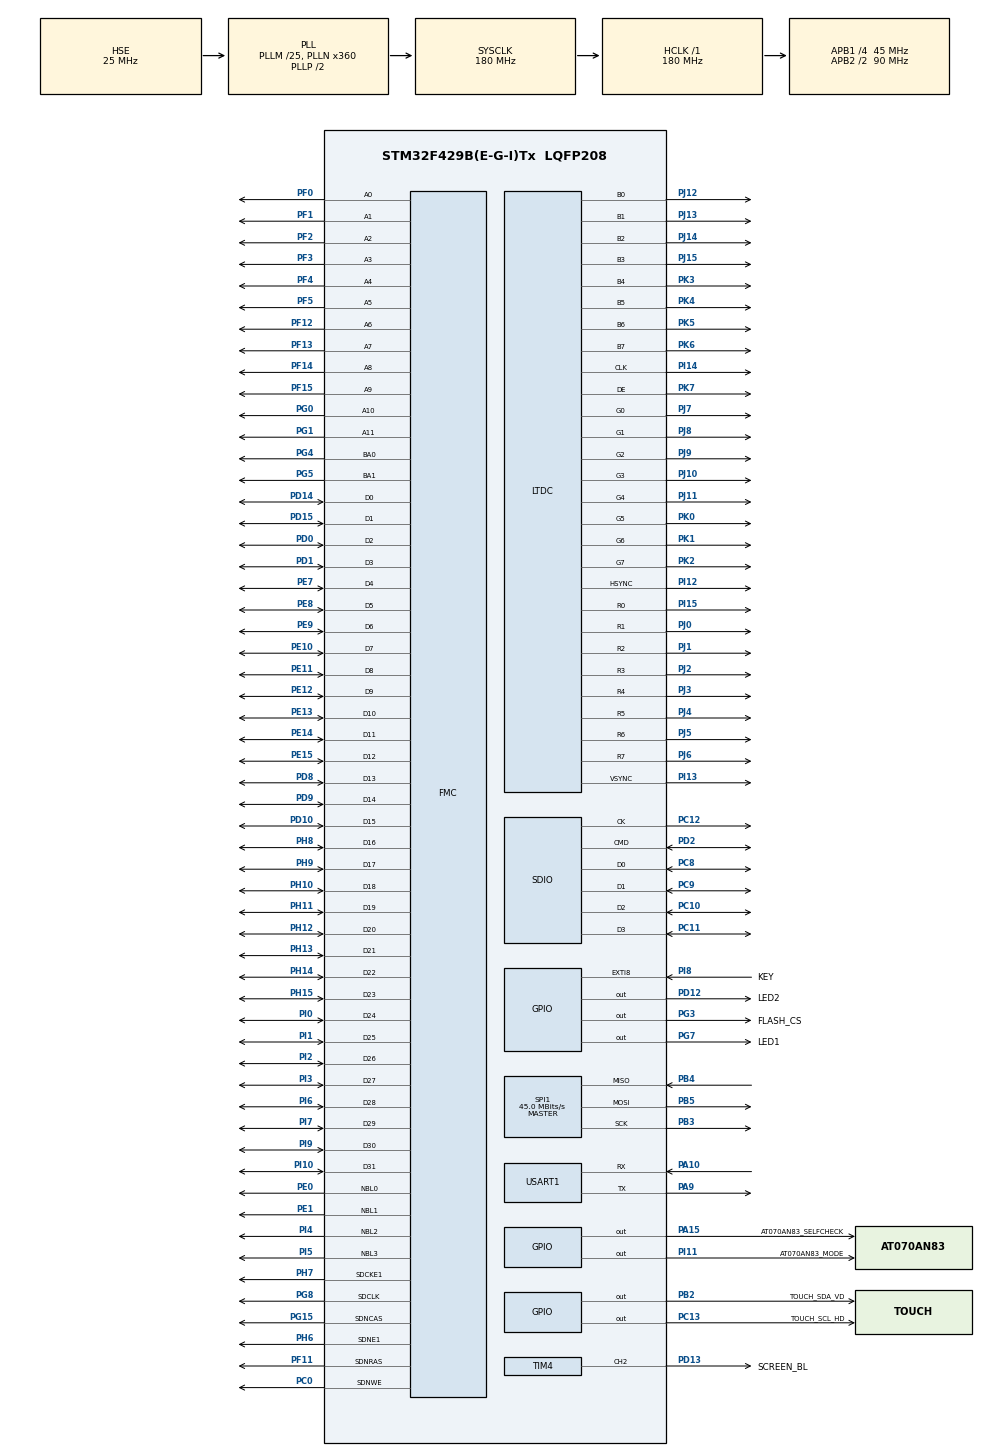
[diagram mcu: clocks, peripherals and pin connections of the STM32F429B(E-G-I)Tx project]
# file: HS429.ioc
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Dma.MEMTOMEM.2.Direction=DMA_MEMORY_TO_MEMORY
Dma.MEMTOMEM.2.FIFOMode=DMA_FIFOMODE_ENABLE
Dma.MEMTOMEM.2.FIFOThreshold=DMA_FIFO_THRESHOLD_FULL
Dma.MEMTOMEM.2.Instance=DMA2_Stream0
Dma.MEMTOMEM.2.MemBurst=DMA_MBURST_SINGLE
Dma.MEMTOMEM.2.MemDataAlignment=DMA_MDATAALIGN_BYTE
Dma.MEMTOMEM.2.MemInc=DMA_MINC_ENABLE
Dma.MEMTOMEM.2.Mode=DMA_NORMAL
Dma.MEMTOMEM.2.PeriphBurst=DMA_PBURST_SINGLE
Dma.MEMTOMEM.2.PeriphDataAlignment=DMA_PDATAALIGN_BYTE
Dma.MEMTOMEM.2.PeriphInc=DMA_PINC_ENABLE
Dma.MEMTOMEM.2.Priority=DMA_PRIORITY_MEDIUM
Dma.Request0=SDIO_RX
Dma.Request1=SDIO_TX
Dma.Request2=MEMTOMEM
Dma.SDIO_RX.0.Direction=DMA_PERIPH_TO_MEMORY
Dma.SDIO_RX.0.FIFOMode=DMA_FIFOMODE_ENABLE
Dma.SDIO_RX.0.FIFOThreshold=DMA_FIFO_THRESHOLD_FULL
Dma.SDIO_RX.0.Instance=DMA2_Stream3
Dma.SDIO_RX.0.MemBurst=DMA_MBURST_INC4
Dma.SDIO_RX.0.MemDataAlignment=DMA_MDATAALIGN_WORD
Dma.SDIO_RX.0.MemInc=DMA_MINC_ENABLE
Dma.SDIO_RX.0.Mode=DMA_PFCTRL
Dma.SDIO_RX.0.PeriphBurst=DMA_PBURST_INC4
Dma.SDIO_RX.0.PeriphDataAlignment=DMA_PDATAALIGN_WORD
Dma.SDIO_RX.0.PeriphInc=DMA_PINC_DISABLE
Dma.SDIO_RX.0.Priority=DMA_PRIORITY_LOW
Dma.SDIO_TX.1.Direction=DMA_MEMORY_TO_PERIPH
Dma.SDIO_TX.1.FIFOMode=DMA_FIFOMODE_ENABLE
Dma.SDIO_TX.1.FIFOThreshold=DMA_FIFO_THRESHOLD_FULL
Dma.SDIO_TX.1.Instance=DMA2_Stream6
Dma.SDIO_TX.1.MemBurst=DMA_MBURST_INC4
Dma.SDIO_TX.1.MemDataAlignment=DMA_MDATAALIGN_WORD
Dma.SDIO_TX.1.MemInc=DMA_MINC_ENABLE
Dma.SDIO_TX.1.Mode=DMA_PFCTRL
Dma.SDIO_TX.1.PeriphBurst=DMA_PBURST_INC4
Dma.SDIO_TX.1.PeriphDataAlignment=DMA_PDATAALIGN_WORD
Dma.SDIO_TX.1.PeriphInc=DMA_PINC_DISABLE
Dma.SDIO_TX.1.Priority=DMA_PRIORITY_LOW
FATFS._CODE_PAGE=437
FATFS._FS_RPATH=2
FATFS._MAX_SS=512
FATFS._MIN_SS=512
FATFS._USE_CHMOD=0
FATFS._USE_LABEL=0
FMC.CASLatency1=FMC_SDRAM_CAS_LATENCY_3
FMC.ExitSelfRefreshDelay1=7
FMC.LoadToActiveDelay1=2
FMC.RCDDelay1=2
FMC.RPDelay1=2
FMC.RPDelay2=2
FMC.ReadBurst1=FMC_SDRAM_RBURST_ENABLE
FMC.ReadBurst2=FMC_SDRAM_RBURST_ENABLE
FMC.ReadPipeDelay1=FMC_SDRAM_RPIPE_DELAY_1
FMC.ReadPipeDelay2=FMC_SDRAM_RPIPE_DELAY_1
FMC.RowCycleDelay1=7
FMC.RowCycleDelay2=7
FMC.SDClockPeriod1=FMC_SDRAM_CLOCK_PERIOD_2
FMC.SDClockPeriod2=FMC_SDRAM_CLOCK_PERIOD_2
FMC.SelfRefreshTime1=4
FMC.WriteRecoveryTime1=3
FREERTOS.Tasks01=defaultTask,0,512,StartDefaultTask,Default,NULL,Dynamic,NULL,NULL
FREERTOS.configTOTAL_HEAP_SIZE=102400
GRAPHICS.Check_OTM8009A_PixelFormat-STemWin_F429_439=1
GRAPHICS.DMA2D_Graphics-STemWin_F429_439=0
GRAPHICS.EA_1_Apptype=Window
GRAPHICS.EA_1_executable_name-STemWin_F429_439=GUIBuilder.exe
GRAPHICS.GUI_DefaultFont=Font8x16
GRAPHICS.GUI_NUM_LAYERS-STemWin_F429_439=1
GRAPHICS.GUI_Num_KBYTES=512
GRAPHICS.GUI_RGB_ORDERING=ARGB
GRAPHICS.LIN_Color_Conversion_Layer0=GUICC_M565
GRAPHICS.LIN_Frame_Buffer_Depth_Layer0-STemWin_F429_439=16
GRAPHICS.Num_MultBuffers=1
GRAPHICS.OPTIM_OS_use-STemWin_F429_439=2
GRAPHICS.USE_Embedded_Wizard-STemWin_F429_439=0
GRAPHICS.USE_STTouchGFX-STemWin_F429_439=0
GRAPHICS.UseGUIBuilder=Enabled
GRAPHICS.Use_SDRAM-STemWin_F429_439=SDRAM1_BANK2
GRAPHICS.Use_ili9341=0
GRAPHICS.Use_ili9341_Check-STemWin_F429_439=0
GRAPHICS.Xsize_PHYS=800
GRAPHICS.Ysize_PHYS=480
LTDC.ActiveW=800
LTDC.Alpha_L0=0xff
LTDC.Alpha_L1=0x7f
LTDC.BlendingFactor1_L1=LTDC_BLENDING_FACTOR1_CA
LTDC.BlendingFactor2_L1=LTDC_BLENDING_FACTOR2_CA
LTDC.FBStartAdress_L0=0xD0D00000
LTDC.FBStartAdress_L1=0xD0F00000
LTDC.HBP=46
LTDC.HFP=200
LTDC.HSync=20
LTDC.ImageHeight_L0=480
LTDC.ImageHeight_L1=480
LTDC.ImageWidth_L0=800
LTDC.ImageWidth_L1=800
LTDC.Layers=0
LTDC.PixelFormat_L0=LTDC_PIXEL_FORMAT_RGB565
LTDC.PixelFormat_L1=LTDC_PIXEL_FORMAT_RGB565
LTDC.VBP=23
LTDC.VFP=22
LTDC.VSync=3
LTDC.WindowX1_L0=800
LTDC.WindowX1_L1=800
LTDC.WindowY1_L0=480
LTDC.WindowY1_L1=480
Mcu.Family=STM32F4
Mcu.Name=STM32F429B(E-G-I)Tx
Mcu.Package=LQFP208
NVIC.DMA2_Stream3_IRQn=true\:5\:0\:false\:false\:true\:true\:false
NVIC.DMA2_Stream6_IRQn=true\:5\:0\:false\:false\:true\:true\:false
NVIC.EXTI9_5_IRQn=true\:5\:0\:false\:false\:true\:true\:true
NVIC.PriorityGroup=NVIC_PRIORITYGROUP_4
NVIC.SDIO_IRQn=true\:5\:0\:true\:false\:true\:true\:true
NVIC.TIM8_TRG_COM_TIM14_IRQn=true\:0\:0\:false\:false\:true\:false\:false
NVIC.TimeBase=TIM8_TRG_COM_TIM14_IRQn
NVIC.TimeBaseIP=TIM14
NVIC.USART1_IRQn=true\:5\:0\:false\:false\:true\:true\:true
PA10.Mode=Asynchronous
PA10.Signal=USART1_RX
PA13.Mode=Serial_Wire
PA13.Signal=SYS_JTMS-SWDIO
PA14.Mode=Serial_Wire
PA14.Signal=SYS_JTCK-SWCLK
PA15.GPIO_Label=AT070AN83_SELFCHECK
PA15.Signal=GPIO_Output
PA9.Mode=Asynchronous
PA9.Signal=USART1_TX
PB2/BOOT1.GPIO_Label=TOUCH_SDA_VD
PB2/BOOT1.GPIO_Speed=GPIO_SPEED_FREQ_VERY_HIGH
PB2/BOOT1.Signal=GPIO_Output
PB3.GPIO_PuPd=GPIO_PULLUP
PB3.Mode=Full_Duplex_Master
PB3.Signal=SPI1_SCK
PB4.GPIO_PuPd=GPIO_PULLUP
PB4.Mode=Full_Duplex_Master
PB4.Signal=SPI1_MISO
PB5.GPIO_PuPd=GPIO_PULLUP
PB5.Mode=Full_Duplex_Master
PB5.Signal=SPI1_MOSI
PC0.Signal=FMC_SDNWE
PC10.Mode=SD_4_bits_Wide_bus
PC10.Signal=SDIO_D2
PC11.Mode=SD_4_bits_Wide_bus
PC11.Signal=SDIO_D3
PC12.Mode=SD_4_bits_Wide_bus
PC12.Signal=SDIO_CK
PC13.GPIO_Label=TOUCH_SCL_HD
PC13.PinState=GPIO_PIN_SET
PC13.Signal=GPIO_Output
PC14/OSC32_IN.Mode=LSE-External-Oscillator
PC14/OSC32_IN.Signal=RCC_OSC32_IN
PC15/OSC32_OUT.Mode=LSE-External-Oscillator
PC15/OSC32_OUT.Signal=RCC_OSC32_OUT
PC8.Mode=SD_4_bits_Wide_bus
PC8.Signal=SDIO_D0
PC9.Mode=SD_4_bits_Wide_bus
PC9.Signal=SDIO_D1
PD0.Signal=FMC_D2_DA2
PD1.Signal=FMC_D3_DA3
PD10.Signal=FMC_D15_DA15
PD12.GPIO_Label=LED2
PD12.GPIO_Speed=GPIO_SPEED_FREQ_MEDIUM
PD12.Signal=GPIO_Output
PD13.GPIO_Label=SCREEN_BL
PD13.GPIO_Speed=GPIO_SPEED_FREQ_VERY_HIGH
PD13.Signal=S_TIM4_CH2
PD14.Signal=FMC_D0_DA0
PD15.Signal=FMC_D1_DA1
PD2.Mode=SD_4_bits_Wide_bus
PD2.Signal=SDIO_CMD
PD8.Signal=FMC_D13_DA13
PD9.Signal=FMC_D14_DA14
PE0.Signal=FMC_NBL0
PE1.Signal=FMC_NBL1
PE10.Signal=FMC_D7_DA7
PE11.Signal=FMC_D8_DA8
PE12.Signal=FMC_D9_DA9
PE13.Signal=FMC_D10_DA10
PE14.Signal=FMC_D11_DA11
PE15.Signal=FMC_D12_DA12
PE7.Signal=FMC_D4_DA4
PE8.Signal=FMC_D5_DA5
PE9.Signal=FMC_D6_DA6
PF0.Signal=FMC_A0
PF1.Signal=FMC_A1
PF11.Signal=FMC_SDNRAS
PF12.Signal=FMC_A6
PF13.Signal=FMC_A7
PF14.Signal=FMC_A8
PF15.Signal=FMC_A9
PF2.Signal=FMC_A2
PF3.Signal=FMC_A3
PF4.Signal=FMC_A4
PF5.Signal=FMC_A5
PG0.Signal=FMC_A10
PG1.Signal=FMC_A11
PG15.Signal=FMC_SDNCAS
PG3.GPIO_Label=FLASH_CS
PG3.GPIO_Speed=GPIO_SPEED_FREQ_HIGH
PG3.Signal=GPIO_Output
PG4.Signal=FMC_A14_BA0
PG5.Signal=FMC_A15_BA1
PG7.GPIO_Label=LED1
PG7.GPIO_Speed=GPIO_SPEED_FREQ_MEDIUM
PG7.Signal=GPIO_Output
PG8.Signal=FMC_SDCLK
PH0/OSC_IN.Mode=HSE-External-Oscillator
PH0/OSC_IN.Signal=RCC_OSC_IN
PH1/OSC_OUT.Mode=HSE-External-Oscillator
PH1/OSC_OUT.Signal=RCC_OSC_OUT
PH10.Signal=FMC_D18
PH11.Signal=FMC_D19
PH12.Signal=FMC_D20
PH13.Signal=FMC_D21
PH14.Signal=FMC_D22
PH15.Signal=FMC_D23
PH6.Mode=SdramChipSelect2_1
PH6.Signal=FMC_SDNE1
PH7.Mode=SdramChipSelect2_1
PH7.Signal=FMC_SDCKE1
PH8.Signal=FMC_D16
PH9.Signal=FMC_D17
PI0.Signal=FMC_D24
PI1.Signal=FMC_D25
PI10.Signal=FMC_D31
PI11.GPIO_Label=AT070AN83_MODE
PI11.PinState=GPIO_PIN_SET
PI11.Signal=GPIO_Output
PI12.GPIO_Speed=GPIO_SPEED_FREQ_VERY_HIGH
PI12.Mode=RGB888
PI12.Signal=LTDC_HSYNC
PI13.GPIO_Speed=GPIO_SPEED_FREQ_VERY_HIGH
PI13.Mode=RGB888
PI13.Signal=LTDC_VSYNC
PI14.GPIO_Speed=GPIO_SPEED_FREQ_VERY_HIGH
PI14.Mode=RGB888
PI14.Signal=LTDC_CLK
PI15.GPIO_Speed=GPIO_SPEED_FREQ_VERY_HIGH
PI15.Mode=RGB888
PI15.Signal=LTDC_R0
PI2.Signal=FMC_D26
PI3.Signal=FMC_D27
PI4.Signal=FMC_NBL2
PI5.Signal=FMC_NBL3
PI6.Signal=FMC_D28
PI7.Signal=FMC_D29
PI8.GPIO_Label=KEY
PI8.GPIO_ModeDefaultEXTI=GPIO_MODE_IT_FALLING
PI8.GPIO_PuPd=GPIO_PULLUP
PI8.Signal=GPXTI8
PI9.Signal=FMC_D30
PJ0.GPIO_Speed=GPIO_SPEED_FREQ_VERY_HIGH
PJ0.Mode=RGB888
PJ0.Signal=LTDC_R1
PJ1.GPIO_Speed=GPIO_SPEED_FREQ_VERY_HIGH
PJ1.Mode=RGB888
PJ1.Signal=LTDC_R2
PJ10.GPIO_Speed=GPIO_SPEED_FREQ_VERY_HIGH
PJ10.Mode=RGB888
PJ10.Signal=LTDC_G3
PJ11.GPIO_Speed=GPIO_SPEED_FREQ_VERY_HIGH
PJ11.Mode=RGB888
PJ11.Signal=LTDC_G4
PJ12.GPIO_Speed=GPIO_SPEED_FREQ_VERY_HIGH
PJ12.Mode=RGB888
PJ12.Signal=LTDC_B0
PJ13.GPIO_Speed=GPIO_SPEED_FREQ_VERY_HIGH
PJ13.Mode=RGB888
PJ13.Signal=LTDC_B1
PJ14.GPIO_Speed=GPIO_SPEED_FREQ_VERY_HIGH
PJ14.Mode=RGB888
PJ14.Signal=LTDC_B2
PJ15.GPIO_Speed=GPIO_SPEED_FREQ_VERY_HIGH
PJ15.Mode=RGB888
PJ15.Signal=LTDC_B3
PJ2.GPIO_Speed=GPIO_SPEED_FREQ_VERY_HIGH
PJ2.Mode=RGB888
PJ2.Signal=LTDC_R3
PJ3.GPIO_Speed=GPIO_SPEED_FREQ_VERY_HIGH
PJ3.Mode=RGB888
PJ3.Signal=LTDC_R4
PJ4.GPIO_Speed=GPIO_SPEED_FREQ_VERY_HIGH
PJ4.Mode=RGB888
PJ4.Signal=LTDC_R5
PJ5.GPIO_Speed=GPIO_SPEED_FREQ_VERY_HIGH
PJ5.Mode=RGB888
PJ5.Signal=LTDC_R6
PJ6.GPIO_Speed=GPIO_SPEED_FREQ_VERY_HIGH
PJ6.Mode=RGB888
PJ6.Signal=LTDC_R7
PJ7.GPIO_Speed=GPIO_SPEED_FREQ_VERY_HIGH
PJ7.Mode=RGB888
PJ7.Signal=LTDC_G0
PJ8.GPIO_Speed=GPIO_SPEED_FREQ_VERY_HIGH
PJ8.Mode=RGB888
PJ8.Signal=LTDC_G1
PJ9.GPIO_Speed=GPIO_SPEED_FREQ_VERY_HIGH
PJ9.Mode=RGB888
PJ9.Signal=LTDC_G2
PK0.GPIO_Speed=GPIO_SPEED_FREQ_VERY_HIGH
PK0.Mode=RGB888
PK0.Signal=LTDC_G5
PK1.GPIO_Speed=GPIO_SPEED_FREQ_VERY_HIGH
PK1.Mode=RGB888
PK1.Signal=LTDC_G6
PK2.GPIO_Speed=GPIO_SPEED_FREQ_VERY_HIGH
PK2.Mode=RGB888
PK2.Signal=LTDC_G7
PK3.GPIO_Speed=GPIO_SPEED_FREQ_VERY_HIGH
PK3.Mode=RGB888
PK3.Signal=LTDC_B4
PK4.GPIO_Speed=GPIO_SPEED_FREQ_VERY_HIGH
PK4.Mode=RGB888
PK4.Signal=LTDC_B5
PK5.GPIO_Speed=GPIO_SPEED_FREQ_VERY_HIGH
PK5.Mode=RGB888
PK5.Signal=LTDC_B6
PK6.GPIO_Speed=GPIO_SPEED_FREQ_VERY_HIGH
PK6.Mode=RGB888
PK6.Signal=LTDC_B7
PK7.GPIO_Speed=GPIO_SPEED_FREQ_VERY_HIGH
PK7.Mode=RGB888
PK7.Signal=LTDC_DE
ProjectManager.HeapSize=0x2000
ProjectManager.StackSize=0x4000
ProjectManager.TargetToolchain=MDK-ARM V5
RCC.48MHZClocksFreq_Value=45000000
RCC.AHBFreq_Value=180000000
RCC.APB1CLKDivider=RCC_HCLK_DIV4
RCC.APB1Freq_Value=45000000
RCC.APB1TimFreq_Value=90000000
RCC.APB2CLKDivider=RCC_HCLK_DIV2
RCC.APB2Freq_Value=90000000
RCC.APB2TimFreq_Value=180000000
RCC.CortexFreq_Value=180000000
RCC.HCLKFreq_Value=180000000
RCC.HSE_VALUE=25000000
RCC.HSI_VALUE=16000000
RCC.PLLM=25
RCC.PLLN=360
RCC.PLLQ=8
RCC.PLLSAIN=198
RCC.PLLSAIR=3
RCC.PLLSourceVirtual=RCC_PLLSOURCE_HSE
RCC.RCC_RTC_Clock_Source=RCC_RTCCLKSOURCE_LSE
RCC.RCC_RTC_Clock_SourceVirtual=RCC_RTCCLKSOURCE_LSE
RCC.SYSCLKFreq_VALUE=180000000
RCC.SYSCLKSource=RCC_SYSCLKSOURCE_PLLCLK
RCC.VCOOutputFreq_Value=360000000
SDIO.ClockDiv=4
SH.FMC_A0.0=FMC_A0,12b-sda1
SH.FMC_A1.0=FMC_A1,12b-sda1
SH.FMC_A10.0=FMC_A10,12b-sda1
SH.FMC_A11.0=FMC_A11,12b-sda1
SH.FMC_A14_BA0.0=FMC_BA0,FourSdramBanks1
SH.FMC_A15_BA1.0=FMC_BA1,FourSdramBanks1
SH.FMC_A2.0=FMC_A2,12b-sda1
SH.FMC_A3.0=FMC_A3,12b-sda1
SH.FMC_A4.0=FMC_A4,12b-sda1
SH.FMC_A5.0=FMC_A5,12b-sda1
SH.FMC_A6.0=FMC_A6,12b-sda1
SH.FMC_A7.0=FMC_A7,12b-sda1
SH.FMC_A8.0=FMC_A8,12b-sda1
SH.FMC_A9.0=FMC_A9,12b-sda1
SH.FMC_D0_DA0.0=FMC_D0,sd-32b-d1
SH.FMC_D10_DA10.0=FMC_D10,sd-32b-d1
SH.FMC_D11_DA11.0=FMC_D11,sd-32b-d1
SH.FMC_D12_DA12.0=FMC_D12,sd-32b-d1
SH.FMC_D13_DA13.0=FMC_D13,sd-32b-d1
SH.FMC_D14_DA14.0=FMC_D14,sd-32b-d1
SH.FMC_D15_DA15.0=FMC_D15,sd-32b-d1
SH.FMC_D16.0=FMC_D16,sd-32b-d1
SH.FMC_D17.0=FMC_D17,sd-32b-d1
SH.FMC_D18.0=FMC_D18,sd-32b-d1
SH.FMC_D19.0=FMC_D19,sd-32b-d1
SH.FMC_D1_DA1.0=FMC_D1,sd-32b-d1
SH.FMC_D20.0=FMC_D20,sd-32b-d1
SH.FMC_D21.0=FMC_D21,sd-32b-d1
SH.FMC_D22.0=FMC_D22,sd-32b-d1
SH.FMC_D23.0=FMC_D23,sd-32b-d1
SH.FMC_D24.0=FMC_D24,sd-32b-d1
SH.FMC_D25.0=FMC_D25,sd-32b-d1
SH.FMC_D26.0=FMC_D26,sd-32b-d1
SH.FMC_D27.0=FMC_D27,sd-32b-d1
SH.FMC_D28.0=FMC_D28,sd-32b-d1
SH.FMC_D29.0=FMC_D29,sd-32b-d1
SH.FMC_D2_DA2.0=FMC_D2,sd-32b-d1
SH.FMC_D30.0=FMC_D30,sd-32b-d1
SH.FMC_D31.0=FMC_D31,sd-32b-d1
SH.FMC_D3_DA3.0=FMC_D3,sd-32b-d1
SH.FMC_D4_DA4.0=FMC_D4,sd-32b-d1
SH.FMC_D5_DA5.0=FMC_D5,sd-32b-d1
SH.FMC_D6_DA6.0=FMC_D6,sd-32b-d1
SH.FMC_D7_DA7.0=FMC_D7,sd-32b-d1
SH.FMC_D8_DA8.0=FMC_D8,sd-32b-d1
SH.FMC_D9_DA9.0=FMC_D9,sd-32b-d1
SH.FMC_NBL0.0=FMC_NBL0,Sd4ByteEnable1
SH.FMC_NBL1.0=FMC_NBL1,Sd4ByteEnable1
SH.FMC_NBL2.0=FMC_NBL2,Sd4ByteEnable1
SH.FMC_NBL3.0=FMC_NBL3,Sd4ByteEnable1
SH.FMC_SDCLK.0=FMC_SDCLK,12b-sda1
SH.FMC_SDNCAS.0=FMC_SDNCAS,12b-sda1
SH.FMC_SDNRAS.0=FMC_SDNRAS,12b-sda1
SH.FMC_SDNWE.0=FMC_SDNWE,12b-sda1
SH.S_TIM4_CH2.0=TIM4_CH2,PWM Generation2 CH2
SPI1.BaudRatePrescaler=SPI_BAUDRATEPRESCALER_2
SPI1.CLKPhase=SPI_PHASE_2EDGE
SPI1.CLKPolarity=SPI_POLARITY_HIGH
SPI1.CalculateBaudRate=45.0 MBits/s
SPI1.Direction=SPI_DIRECTION_2LINES
SPI1.Mode=SPI_MODE_MASTER
SPI1.VirtualType=VM_MASTER
TIM4.Channel-PWM\ Generation2\ CH2=TIM_CHANNEL_2
TIM4.Period=5000
TIM4.Prescaler=89
TIM4.Pulse-PWM\ Generation2\ CH2=2000
USART1.VirtualMode=VM_ASYNC
VP_CRC_VS_CRC.Mode=CRC_Activate
VP_FATFS_VS_Generic.Mode=User_defined
VP_FATFS_VS_SDIO.Mode=SDIO
VP_FREERTOS_VS_ENABLE.Mode=Enabled
VP_GRAPHICS_VS-DisplayInterface-LTDC.Mode=Display Parallel Interface using LTDC
VP_GRAPHICS_VS-STemWin.Mode=STemWin_F429_439
VP_RNG_VS_RNG.Mode=RNG_Activate
VP_RTC_VS_RTC_Activate.Mode=RTC_Enabled
VP_SYS_VS_tim14.Mode=TIM14
board=custom

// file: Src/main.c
/**
  ******************************************************************************
  * @file           : main.c
  * @brief          : Main program body
  ******************************************************************************
  * This notice applies to any and all portions of this file
  * that are not between comment pairs USER CODE BEGIN and
  * USER CODE END. Other portions of this file, whether
  * inserted by the user or by software development tools
  * are owned by their respective copyright owners.
  *
  * Copyright (c) 2018 STMicroelectronics International N.V.
  * All rights reserved.
  *
  * Redistribution and use in source and binary forms, with or without
  * modification, are permitted, provided that the following conditions are met:
  *
  * 1. Redistribution of source code must retain the above copyright notice,
  *    this list of conditions and the following disclaimer.
  * 2. Redistributions in binary form must reproduce the above copyright notice,
  *    this list of conditions and the following disclaimer in the documentation
  *    and/or other materials provided with the distribution.
  * 3. Neither the name of STMicroelectronics nor the names of other
  *    contributors to this software may be used to endorse or promote products
  *    derived from this software without specific written permission.
  * 4. This software, including modifications and/or derivative works of this
  *    software, must execute solely and exclusively on microcontroller or
  *    microprocessor devices manufactured by or for STMicroelectronics.
  * 5. Redistribution and use of this software other than as permitted under
  *    this license is void and will automatically terminate your rights under
  *    this license.
  *
  * THIS SOFTWARE IS PROVIDED BY STMICROELECTRONICS AND CONTRIBUTORS "AS IS"
  * AND ANY EXPRESS, IMPLIED OR STATUTORY WARRANTIES, INCLUDING, BUT NOT
  * LIMITED TO, THE IMPLIED WARRANTIES OF MERCHANTABILITY, FITNESS FOR A
  * PARTICULAR PURPOSE AND NON-INFRINGEMENT OF THIRD PARTY INTELLECTUAL PROPERTY
  * RIGHTS ARE DISCLAIMED TO THE FULLEST EXTENT PERMITTED BY LAW. IN NO EVENT
  * SHALL STMICROELECTRONICS OR CONTRIBUTORS BE LIABLE FOR ANY DIRECT, INDIRECT,
  * INCIDENTAL, SPECIAL, EXEMPLARY, OR CONSEQUENTIAL DAMAGES (INCLUDING, BUT NOT
  * LIMITED TO, PROCUREMENT OF SUBSTITUTE GOODS OR SERVICES; LOSS OF USE, DATA,
  * OR PROFITS; OR BUSINESS INTERRUPTION) HOWEVER CAUSED AND ON ANY THEORY OF
  * LIABILITY, WHETHER IN CONTRACT, STRICT LIABILITY, OR TORT (INCLUDING
  * NEGLIGENCE OR OTHERWISE) ARISING IN ANY WAY OUT OF THE USE OF THIS SOFTWARE,
  * EVEN IF ADVISED OF THE POSSIBILITY OF SUCH DAMAGE.
  *
  ******************************************************************************
  */
#include "main.h"
#include "stm32f4xx_hal.h"
#include "cmsis_os.h"
#include "crc.h"
#include "dma.h"
#include "fatfs.h"
#include "rng.h"
#include "rtc.h"
#include "sdio.h"
#include "spi.h"
#include "tim.h"
#include "usart.h"
#include "gpio.h"

/* USER CODE BEGIN Includes */
#include "bsp_driver_flash.h"
#include "mem.h"
#include "touch.h"

/* USER CODE END Includes */

/* USER CODE BEGIN PV */
/* Private variables ---------------------------------------------------------*/
extern uint8_t uartRevValue;

/* USER CODE END PV */

void SystemClock_Config(void);
void MX_FREERTOS_Init(void);
extern void GRAPHICS_HW_Init(void);
extern void GRAPHICS_Init(void);
extern void GRAPHICS_MainTask(void);

/* USER CODE BEGIN PFP */
/* Private function prototypes -----------------------------------------------*/

/* USER CODE END PFP */

/* USER CODE BEGIN 0 */
int fputc(int ch, FILE* stream)
{
    UART1_PrintChar((uint8_t)ch);
    return ch;
}
/* USER CODE END 0 */

int main(void)
{

  /* MCU Configuration----------------------------------------------------------*/

  /* Reset of all peripherals, Initializes the Flash interface and the Systick. */
  HAL_Init();

  /* Configure the system clock */
  SystemClock_Config();

  /* Initialize all configured peripherals */
  MX_GPIO_Init();
  MX_DMA_Init();
  MX_RTC_Init();
  MX_SDIO_SD_Init();
  MX_USART1_UART_Init();
  MX_CRC_Init();
  MX_SPI1_Init();
  MX_TIM4_Init();
  MX_RNG_Init();
  /* USER CODE BEGIN 2 */
    //附加启动
    HAL_UART_Receive_IT(&huart1, &uartRevValue, 1);
    UART1_PrintLn("UART1 Open...");
    TOUCH_Init();   //初始化触摸屏
    HAL_TIM_PWM_Start(&htim4,TIM_CHANNEL_2);  //40%亮度

    //用户代码
    HAL_GPIO_WritePin(LED1_GPIO_Port,LED1_Pin,GPIO_PIN_SET);
    mallocInit();

  /* USER CODE END 2 */

/* Initialise the graphical hardware */
  GRAPHICS_HW_Init();

  /* Initialise the graphical stack engine */
  GRAPHICS_Init();

  /* Call init function for freertos objects (in freertos.c) */
  MX_FREERTOS_Init();

  /* Start scheduler */
  osKernelStart();

  /* We should never get here as control is now taken by the scheduler */

  /* Infinite loop */
  while (1)
  {

  }

}

void SystemClock_Config(void)
{

  RCC_OscInitTypeDef RCC_OscInitStruct;
  RCC_ClkInitTypeDef RCC_ClkInitStruct;
  RCC_PeriphCLKInitTypeDef PeriphClkInitStruct;

    /**Configure the main internal regulator output voltage
    */
  __HAL_RCC_PWR_CLK_ENABLE();

  __HAL_PWR_VOLTAGESCALING_CONFIG(PWR_REGULATOR_VOLTAGE_SCALE1);

    /**Initializes the CPU, AHB and APB busses clocks
    */
  RCC_OscInitStruct.OscillatorType = RCC_OSCILLATORTYPE_HSE|RCC_OSCILLATORTYPE_LSE;
  RCC_OscInitStruct.HSEState = RCC_HSE_ON;
  RCC_OscInitStruct.LSEState = RCC_LSE_ON;
  RCC_OscInitStruct.PLL.PLLState = RCC_PLL_ON;
  RCC_OscInitStruct.PLL.PLLSource = RCC_PLLSOURCE_HSE;
  RCC_OscInitStruct.PLL.PLLM = 25;
  RCC_OscInitStruct.PLL.PLLN = 360;
  RCC_OscInitStruct.PLL.PLLP = RCC_PLLP_DIV2;
  RCC_OscInitStruct.PLL.PLLQ = 8;
  if (HAL_RCC_OscConfig(&RCC_OscInitStruct) != HAL_OK)
  {
    _Error_Handler(__FILE__, __LINE__);
  }

    /**Activate the Over-Drive mode
    */
  if (HAL_PWREx_EnableOverDrive() != HAL_OK)
  {
    _Error_Handler(__FILE__, __LINE__);
  }

    /**Initializes the CPU, AHB and APB busses clocks
    */
  RCC_ClkInitStruct.ClockType = RCC_CLOCKTYPE_HCLK|RCC_CLOCKTYPE_SYSCLK
                              |RCC_CLOCKTYPE_PCLK1|RCC_CLOCKTYPE_PCLK2;
  RCC_ClkInitStruct.SYSCLKSource = RCC_SYSCLKSOURCE_PLLCLK;
  RCC_ClkInitStruct.AHBCLKDivider = RCC_SYSCLK_DIV1;
  RCC_ClkInitStruct.APB1CLKDivider = RCC_HCLK_DIV4;
  RCC_ClkInitStruct.APB2CLKDivider = RCC_HCLK_DIV2;

  if (HAL_RCC_ClockConfig(&RCC_ClkInitStruct, FLASH_LATENCY_5) != HAL_OK)
  {
    _Error_Handler(__FILE__, __LINE__);
  }

  PeriphClkInitStruct.PeriphClockSelection = RCC_PERIPHCLK_LTDC|RCC_PERIPHCLK_RTC;
  PeriphClkInitStruct.PLLSAI.PLLSAIN = 198;
  PeriphClkInitStruct.PLLSAI.PLLSAIR = 3;
  PeriphClkInitStruct.PLLSAIDivR = RCC_PLLSAIDIVR_2;
  PeriphClkInitStruct.RTCClockSelection = RCC_RTCCLKSOURCE_LSE;
  if (HAL_RCCEx_PeriphCLKConfig(&PeriphClkInitStruct) != HAL_OK)
  {
    _Error_Handler(__FILE__, __LINE__);
  }

    /**Configure the Systick interrupt time
    */
  HAL_SYSTICK_Config(HAL_RCC_GetHCLKFreq()/1000);

    /**Configure the Systick
    */
  HAL_SYSTICK_CLKSourceConfig(SYSTICK_CLKSOURCE_HCLK);

  /* SysTick_IRQn interrupt configuration */
  HAL_NVIC_SetPriority(SysTick_IRQn, 15, 0);
}

void HAL_TIM_PeriodElapsedCallback(TIM_HandleTypeDef *htim)
{
  if (htim->Instance == TIM14) {
    HAL_IncTick();
  }
}

void _Error_Handler(char *file, int line)
{
    while(1)
    {
    }
}

/************************ (C) COPYRIGHT STMicroelectronics *****END OF FILE****/

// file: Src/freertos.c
/* USER CODE BEGIN Header */
/**
  ******************************************************************************
  * File Name          : freertos.c
  * Description        : Code for freertos applications
  ******************************************************************************
  * This notice applies to any and all portions of this file
  * that are not between comment pairs USER CODE BEGIN and
  * USER CODE END. Other portions of this file, whether
  * inserted by the user or by software development tools
  * are owned by their respective copyright owners.
  *
  * Copyright (c) 2018 STMicroelectronics International N.V.
  * All rights reserved.
  *
  * Redistribution and use in source and binary forms, with or without
  * modification, are permitted, provided that the following conditions are met:
  *
  * 1. Redistribution of source code must retain the above copyright notice,
  *    this list of conditions and the following disclaimer.
  * 2. Redistributions in binary form must reproduce the above copyright notice,
  *    this list of conditions and the following disclaimer in the documentation
  *    and/or other materials provided with the distribution.
  * 3. Neither the name of STMicroelectronics nor the names of other
  *    contributors to this software may be used to endorse or promote products
  *    derived from this software without specific written permission.
  * 4. This software, including modifications and/or derivative works of this
  *    software, must execute solely and exclusively on microcontroller or
  *    microprocessor devices manufactured by or for STMicroelectronics.
  * 5. Redistribution and use of this software other than as permitted under
  *    this license is void and will automatically terminate your rights under
  *    this license.
  *
  * THIS SOFTWARE IS PROVIDED BY STMICROELECTRONICS AND CONTRIBUTORS "AS IS"
  * AND ANY EXPRESS, IMPLIED OR STATUTORY WARRANTIES, INCLUDING, BUT NOT
  * LIMITED TO, THE IMPLIED WARRANTIES OF MERCHANTABILITY, FITNESS FOR A
  * PARTICULAR PURPOSE AND NON-INFRINGEMENT OF THIRD PARTY INTELLECTUAL PROPERTY
  * RIGHTS ARE DISCLAIMED TO THE FULLEST EXTENT PERMITTED BY LAW. IN NO EVENT
  * SHALL STMICROELECTRONICS OR CONTRIBUTORS BE LIABLE FOR ANY DIRECT, INDIRECT,
  * INCIDENTAL, SPECIAL, EXEMPLARY, OR CONSEQUENTIAL DAMAGES (INCLUDING, BUT NOT
  * LIMITED TO, PROCUREMENT OF SUBSTITUTE GOODS OR SERVICES; LOSS OF USE, DATA,
  * OR PROFITS; OR BUSINESS INTERRUPTION) HOWEVER CAUSED AND ON ANY THEORY OF
  * LIABILITY, WHETHER IN CONTRACT, STRICT LIABILITY, OR TORT (INCLUDING
  * NEGLIGENCE OR OTHERWISE) ARISING IN ANY WAY OUT OF THE USE OF THIS SOFTWARE,
  * EVEN IF ADVISED OF THE POSSIBILITY OF SUCH DAMAGE.
  *
  ******************************************************************************
  */
/* USER CODE END Header */

#include "FreeRTOS.h"
#include "task.h"
#include "main.h"
#include "cmsis_os.h"

/* USER CODE BEGIN Includes */
#include "usart.h"
#include "fatfs.h"
#include "bsp_driver_flash.h"
/* USER CODE END Includes */

/* USER CODE BEGIN Variables */
FIL fil;

u8 datas[1024];
/* USER CODE END Variables */
osThreadId defaultTaskHandle;
osThreadId debugTaskHandle;

void StartDefaultTask(void const * argument);
void StartDebugTask(void const * argument);

extern void MX_FATFS_Init(void);
void MX_FREERTOS_Init(void); /* (MISRA C 2004 rule 8.1) */

void MX_FREERTOS_Init(void) {

  /* Create the thread(s) */
  /* definition and creation of defaultTask */
  osThreadDef(defaultTask, StartDefaultTask, osPriorityNormal, 0, 128);
  defaultTaskHandle = osThreadCreate(osThread(defaultTask), NULL);

  /* definition and creation of debugTask */
  osThreadDef(debugTask, StartDebugTask, osPriorityAboveNormal, 0, 128);
  debugTaskHandle = osThreadCreate(osThread(debugTask), NULL);

}

void StartDefaultTask(void const * argument)
{
  /* init code for FATFS */
  MX_FATFS_Init();

  /* USER CODE BEGIN StartDefaultTask */
    UART1_PrintLn("Default Task Started");
    osDelay(500);
    //=======================fatfs====================

    //FRESULT fr;
    //UART1_PrintLn("FatFS mount...");
    /*
    fr=f_mount(&SDFatFS,"0:",1);
    if(fr != FR_OK)
    {
        if(fr==FR_NO_FILESYSTEM)
        {
            UART1_PrintLn("FatFS SD format...");
            fr=f_mkfs("0:",FM_ANY,0,datas,sizeof(datas));
            if(fr != FR_OK)
                UART1_PrintDataLn("FatFS SD format fail:",fr);
        }
        else
            UART1_PrintDataLn("FatFS SD mount Fail:",fr);

    }
    else
    {
        UART1_PrintLn("FatFS SD mount Success");
    }

    fr=f_mount(&USERFatFS,"1:",1);
    if(fr != FR_OK)
    {
        if(fr==FR_NO_FILESYSTEM)
        {
            UART1_PrintLn("FatFS FLASH format...");
            fr=f_mkfs("1:",FM_ANY,0,datas,sizeof(datas));
            if(fr != FR_OK)
                UART1_PrintDataLn("FatFS FLASH format fail:",fr);
        }
        else
            UART1_PrintDataLn("FatFS FLASH mount Fail:",fr);

    }
    else
    {
        UART1_PrintLn("FatFS FLASH mount Success");
    }

    //�ļ�����

    u32 bw;
    //char line[100];
    fr=f_open(&fil,"1:m.txt",FA_WRITE|FA_CREATE_ALWAYS);
    if(fr==FR_OK)
    {

        UART1_PrintLn("Start write");
        fr=f_write(&fil,"ahhhhhh",5,&bw);
        if(fr!=FR_OK) UART1_PrintLn("write fail");
        f_close(&fil);

    }
    else UART1_PrintLn("create fail");

    //��Ŀ¼��ȡ
    DIR dir;
    FILINFO fno;
    fr=f_opendir(&dir,"1:");
    if(fr==FR_OK)
    {
        for(;;)
        {
            fr = f_readdir(&dir, &fno);
                if (fr != FR_OK || fno.fname[0] == 0)
                {
                    UART1_PrintLn("None");
                    break;
                }
            UART1_Print("Get file:");
            UART1_PrintLn(fno.fname);
        }
        f_closedir(&dir);
    }
    else
    {
        UART1_PrintDataLn("Opendir fail:",fr);
    }
    */

    /* Infinite loop */
    for(;;)
    {
        HAL_GPIO_TogglePin(LED1_GPIO_Port,LED1_Pin);
        osDelay(1000);
    }
  /* USER CODE END StartDefaultTask */
}

void StartDebugTask(void const * argument)
{
  /* USER CODE BEGIN StartDebugTask */
  UART1_PrintLn("Debug Task Started");
    osDelay(750);

    /* Infinite loop */
  for(;;)
  {
      HAL_GPIO_TogglePin(LED2_GPIO_Port,LED2_Pin);
    osDelay(200);
  }
  /* USER CODE END StartDebugTask */
}

/************************ (C) COPYRIGHT STMicroelectronics *****END OF FILE****/
